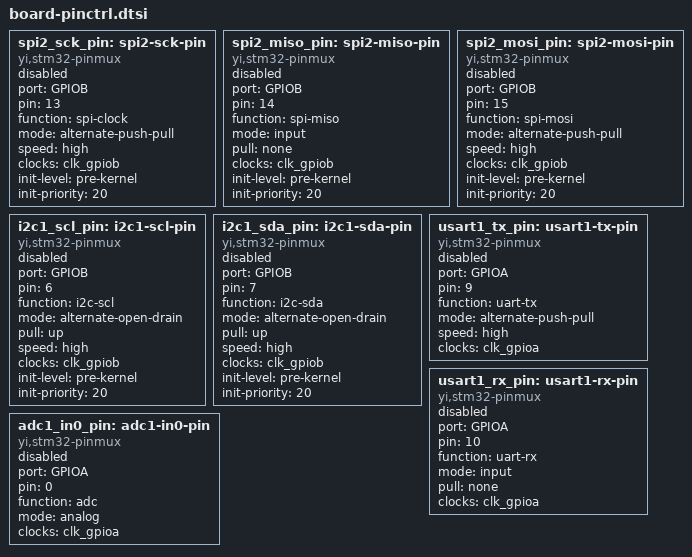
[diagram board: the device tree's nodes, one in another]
    spi2_sck_pin: spi2-sck-pin {
        compatible = "yi,stm32-pinmux";
        port = "GPIOB";
        pin = <13>;
        function = "spi-clock";
        mode = "alternate-push-pull";
        speed = "high";
        clocks = <&clk_gpiob>;
        init-level = "pre-kernel";
        init-priority = <20>;
        status = "available";
    };

    spi2_miso_pin: spi2-miso-pin {
        compatible = "yi,stm32-pinmux";
        port = "GPIOB";
        pin = <14>;
        function = "spi-miso";
        mode = "input";
        pull = "none";
        clocks = <&clk_gpiob>;
        init-level = "pre-kernel";
        init-priority = <20>;
        status = "available";
    };

    spi2_mosi_pin: spi2-mosi-pin {
        compatible = "yi,stm32-pinmux";
        port = "GPIOB";
        pin = <15>;
        function = "spi-mosi";
        mode = "alternate-push-pull";
        speed = "high";
        clocks = <&clk_gpiob>;
        init-level = "pre-kernel";
        init-priority = <20>;
        status = "available";
    };

    i2c1_scl_pin: i2c1-scl-pin {
        compatible = "yi,stm32-pinmux";
        port = "GPIOB";
        pin = <6>;
        function = "i2c-scl";
        mode = "alternate-open-drain";
        pull = "up";
        speed = "high";
        clocks = <&clk_gpiob>;
        init-level = "pre-kernel";
        init-priority = <20>;
        status = "available";
    };

    i2c1_sda_pin: i2c1-sda-pin {
        compatible = "yi,stm32-pinmux";
        port = "GPIOB";
        pin = <7>;
        function = "i2c-sda";
        mode = "alternate-open-drain";
        pull = "up";
        speed = "high";
        clocks = <&clk_gpiob>;
        init-level = "pre-kernel";
        init-priority = <20>;
        status = "available";
    };

    usart1_tx_pin: usart1-tx-pin {
        compatible = "yi,stm32-pinmux";
        port = "GPIOA";
        pin = <9>;
        function = "uart-tx";
        mode = "alternate-push-pull";
        speed = "high";
        clocks = <&clk_gpioa>;
        status = "available";
    };

    usart1_rx_pin: usart1-rx-pin {
        compatible = "yi,stm32-pinmux";
        port = "GPIOA";
        pin = <10>;
        function = "uart-rx";
        mode = "input";
        pull = "none";
        clocks = <&clk_gpioa>;
        status = "available";
    };

    adc1_in0_pin: adc1-in0-pin {
        compatible = "yi,stm32-pinmux";
        port = "GPIOA";
        pin = <0>;
        function = "adc";
        mode = "analog";
        clocks = <&clk_gpioa>;
        status = "available";
    };
